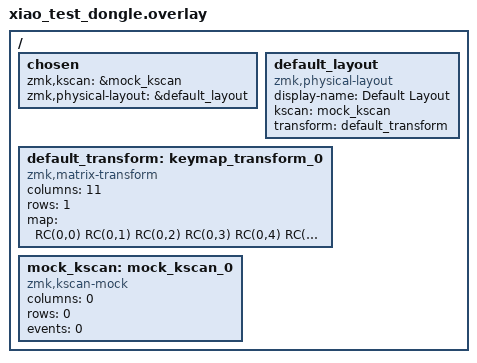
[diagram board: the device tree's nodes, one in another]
/*
 * Copyright (c) 2026 The ZMK Contributors
 *
 * SPDX-License-Identifier: MIT
 */

#include <dt-bindings/zmk/matrix_transform.h>

/ {
    chosen {
        zmk,kscan = &mock_kscan;
        zmk,physical-layout = &default_layout;
    };

    default_layout: default_layout {
        compatible = "zmk,physical-layout";
        display-name = "Default Layout";
        kscan = <&mock_kscan>;
        transform = <&default_transform>;
    };

    default_transform: keymap_transform_0 {
        compatible = "zmk,matrix-transform";
        columns = <11>;
        rows = <1>;
        map = <
            RC(0,0) RC(0,1) RC(0,2) RC(0,3) RC(0,4) RC(0,5) RC(0,6) RC(0,7) RC(0,8) RC(0,9) RC(0,10)
        >;
    };

    mock_kscan: mock_kscan_0 {
        compatible = "zmk,kscan-mock";
        columns = <0>;
        rows = <0>;
        events = <0>;
    };
};
